AUTOSAR XML (schema 4-0-3)
package /ComponentTypes
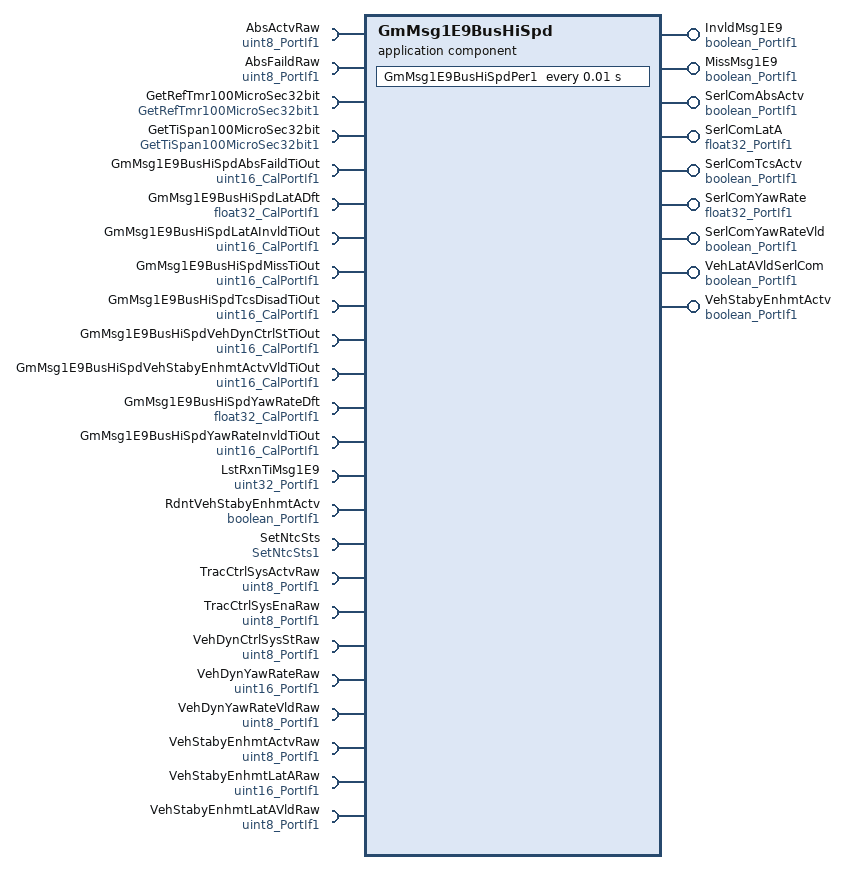
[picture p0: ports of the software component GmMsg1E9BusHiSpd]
  application sw component type GmMsg1E9BusHiSpd
    9 x provide port:
      InvldMsg1E9: nonqueued-sender-com-spec{data-element=Logl, init-value=0}, provided-interface=boolean_PortIf1
      MissMsg1E9: nonqueued-sender-com-spec{data-element=Logl, init-value=0}, provided-interface=boolean_PortIf1
      SerlComAbsActv: nonqueued-sender-com-spec{data-element=Logl, init-value=0}, provided-interface=boolean_PortIf1
      SerlComLatA: nonqueued-sender-com-spec{data-element=Val, init-value=0}, provided-interface=float32_PortIf1
      SerlComTcsActv: nonqueued-sender-com-spec{data-element=Logl, init-value=0}, provided-interface=boolean_PortIf1
      SerlComYawRate: nonqueued-sender-com-spec{data-element=Val, init-value=0}, provided-interface=float32_PortIf1
      SerlComYawRateVld: nonqueued-sender-com-spec{data-element=Logl, init-value=0}, provided-interface=boolean_PortIf1
      VehLatAVldSerlCom: nonqueued-sender-com-spec{data-element=Logl, init-value=0}, provided-interface=boolean_PortIf1
      VehStabyEnhmtActv: nonqueued-sender-com-spec{data-element=Logl, init-value=0}, provided-interface=boolean_PortIf1
    24 x require port:
      AbsActvRaw: nonqueued-receiver-com-spec{data-element=Val, filter=data-filter-type=ALWAYS, init-value=0}, required-interface=uint8_PortIf1
      AbsFaildRaw: nonqueued-receiver-com-spec{data-element=Val, filter=data-filter-type=ALWAYS, init-value=0}, required-interface=uint8_PortIf1
      GetRefTmr100MicroSec32bit: required-interface=GetRefTmr100MicroSec32bit1
      GetTiSpan100MicroSec32bit: required-interface=GetTiSpan100MicroSec32bit1
      GmMsg1E9BusHiSpdAbsFaildTiOut: parameter-require-com-spec{init-value=1000, parameter=Val}, required-interface=uint16_CalPortIf1
      GmMsg1E9BusHiSpdLatADft: parameter-require-com-spec{init-value=0.101937, parameter=Val}, required-interface=float32_CalPortIf1
      GmMsg1E9BusHiSpdLatAInvldTiOut: parameter-require-com-spec{init-value=5000, parameter=Val}, required-interface=uint16_CalPortIf1
      GmMsg1E9BusHiSpdMissTiOut: parameter-require-com-spec{init-value=500, parameter=Val}, required-interface=uint16_CalPortIf1
      GmMsg1E9BusHiSpdTcsDisadTiOut: parameter-require-com-spec{init-value=1000, parameter=Val}, required-interface=uint16_CalPortIf1
      GmMsg1E9BusHiSpdVehDynCtrlStTiOut: parameter-require-com-spec{init-value=1000, parameter=Val}, required-interface=uint16_CalPortIf1
      GmMsg1E9BusHiSpdVehStabyEnhmtActvVldTiOut: parameter-require-com-spec{init-value=1000, parameter=Val}, required-interface=uint16_CalPortIf1
      GmMsg1E9BusHiSpdYawRateDft: parameter-require-com-spec{init-value=50, parameter=Val}, required-interface=float32_CalPortIf1
      GmMsg1E9BusHiSpdYawRateInvldTiOut: parameter-require-com-spec{init-value=5000, parameter=Val}, required-interface=uint16_CalPortIf1
      LstRxnTiMsg1E9: nonqueued-receiver-com-spec{data-element=Val, filter=data-filter-type=ALWAYS, init-value=0}, required-interface=uint32_PortIf1
      RdntVehStabyEnhmtActv: nonqueued-receiver-com-spec{data-element=Logl, filter=data-filter-type=ALWAYS, init-value=0}, required-interface=boolean_PortIf1
      SetNtcSts: required-interface=SetNtcSts1
      TracCtrlSysActvRaw: nonqueued-receiver-com-spec{data-element=Val, filter=data-filter-type=ALWAYS, init-value=0}, required-interface=uint8_PortIf1
      TracCtrlSysEnaRaw: nonqueued-receiver-com-spec{data-element=Val, filter=data-filter-type=ALWAYS, init-value=0}, required-interface=uint8_PortIf1
      VehDynCtrlSysStRaw: nonqueued-receiver-com-spec{data-element=Val, filter=data-filter-type=ALWAYS, init-value=0}, required-interface=uint8_PortIf1
      VehDynYawRateRaw: nonqueued-receiver-com-spec{data-element=Val, filter=data-filter-type=ALWAYS, init-value=0}, required-interface=uint16_PortIf1
      VehDynYawRateVldRaw: nonqueued-receiver-com-spec{data-element=Val, filter=data-filter-type=ALWAYS, init-value=0}, required-interface=uint8_PortIf1
      VehStabyEnhmtActvRaw: nonqueued-receiver-com-spec{data-element=Val, filter=data-filter-type=ALWAYS, init-value=0}, required-interface=uint8_PortIf1
      VehStabyEnhmtLatARaw: nonqueued-receiver-com-spec{data-element=Val, filter=data-filter-type=ALWAYS, init-value=0}, required-interface=uint16_PortIf1
      VehStabyEnhmtLatAVldRaw: nonqueued-receiver-com-spec{data-element=Val, filter=data-filter-type=ALWAYS, init-value=0}, required-interface=uint8_PortIf1
    behavior GmMsg1E9BusHiSpd_InternalBehavior: data-type-mapping=Nexteer
      ar-typed-per-instance-memorys:
        6 x data, all with sw-calibration-access=READ-ONLY, type=uint32:
          GmMsg1E9BusHiSpdAbsFaildTmr
          GmMsg1E9BusHiSpdLatAInvldTmr
          GmMsg1E9BusHiSpdRdntVehStabyEnhmtTmr
          GmMsg1E9BusHiSpdTcsEnaTmr
          GmMsg1E9BusHiSpdVehDynCtrlSysStTmr
          GmMsg1E9BusHiSpdYawRateInvldTmr
      timing event TMT_GM0C9HSPer1: start-on-event=GmMsg1E9BusHiSpdPer1, period=0.01
      runnable GmMsg1E9BusHiSpdPer1
        data-receive-point-by-arguments:
          12 x access:
            REC_AbsActvRaw_Val: accessed-variable=AbsActvRaw.Val
            REC_AbsFaildRaw_Val: accessed-variable=AbsFaildRaw.Val
            REC_Msg0C9HSLstRxnTi_Val: accessed-variable=LstRxnTiMsg1E9.Val
            REC_RdntVehStabyEnhmtActv_Logl: accessed-variable=RdntVehStabyEnhmtActv.Logl
            REC_TracCtrlSysActvRaw_Val: accessed-variable=TracCtrlSysActvRaw.Val
            REC_TracCtrlSysEnaRaw_Val: accessed-variable=TracCtrlSysEnaRaw.Val
            REC_VehDynCtrlSysStRaw_Val: accessed-variable=VehDynCtrlSysStRaw.Val
            REC_VehDynYawRateRaw_Val: accessed-variable=VehDynYawRateRaw.Val
            REC_VehDynYawRateVldRaw_Val: accessed-variable=VehDynYawRateVldRaw.Val
            REC_VehStabyEnhmtActvRaw_Val: accessed-variable=VehStabyEnhmtActvRaw.Val
            REC_VehStabyEnhmtLatARaw_Val: accessed-variable=VehStabyEnhmtLatARaw.Val
            REC_VehStabyEnhmtLatAVldRaw_Val: accessed-variable=VehStabyEnhmtLatAVldRaw.Val
        data-send-points:
          9 x access:
            SEND_InvldMsg1E9_Logl: accessed-variable=InvldMsg1E9.Logl
            SEND_MissMsg1E9_Logl: accessed-variable=MissMsg1E9.Logl
            SEND_SerlComAbsAtv_Logl: accessed-variable=SerlComAbsActv.Logl
            SEND_SerlComLatA_Val: accessed-variable=SerlComLatA.Val
            SEND_SerlComTcsAtv_Logl: accessed-variable=SerlComTcsActv.Logl
            SEND_SerlComYawRate_Val: accessed-variable=SerlComYawRate.Val
            SEND_SerlComYawRateVld_Logl: accessed-variable=SerlComYawRateVld.Logl
            SEND_VehLatAVldSerlCom_Logl: accessed-variable=VehLatAVldSerlCom.Logl
            SEND_VehStabyEnhmtActv_Logl: accessed-variable=VehStabyEnhmtActv.Logl
        sync call SC_GetRefTmr100MicroSec32bit_Oper: operation=GetRefTmr100MicroSec32bit.Oper, timeout=0
        sync call SC_GetTiSpan100MicroSec32bit_Oper: operation=GetTiSpan100MicroSec32bit.Oper, timeout=0
        sync call SC_SetNtcSts_Oper: operation=SetNtcSts.Oper, timeout=0
  swc implementation GmMsg1E9BusHiSpd_Implementation: behavior=GmMsg1E9BusHiSpd_InternalBehavior
    code-descriptors:
      code Default: artifact-descriptors=autosar-engineering-object={short-label=Default, category=SWSRC}
